# FM33LG0XX register map
File version: 1.0
CPU: SC123 r1p0, little endian, no MPU, no FPU, 3 interrupt priority bits
Registers are 32-bit, read-write, reset 0x0 unless marked. A register's access mark holds for its fields unless they carry their own. Offsets are from the block's base; [hi:lo] are bit positions; {n}, {i} and the like mark numbered series.

## SVD — SVD module information
Base 0x40012800
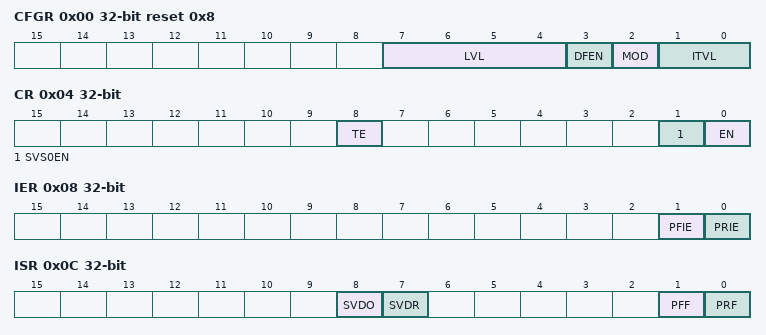
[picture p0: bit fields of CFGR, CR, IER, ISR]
0x00 CFGR reset 0x8 — SVD Config Register
  [7:4] LVL — LVL field description
  [3] DFEN — DFEN field description
  [2] MOD — MOD field description
  [1:0] ITVL — ITVL field description
0x04 CR access per field — SVD Control Register
  [8] TE rw — TE field description
  [1] SVS0EN wo — SVS0EN field description
  [0] EN rw — EN field description
0x08 IER — SVD Interrupt Enable Register
  [1] PFIE — PFIE field description
  [0] PRIE — PRIE field description
0x0C ISR access per field — SVD Interrupt Status Register
  [8] SVDO ro — SVDO field description
  [7] SVDR ro — SVDR field description
  [1] PFF rw — PFF field description
  [0] PRF rw — PRF field description
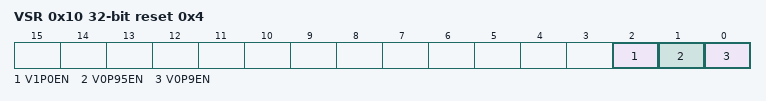
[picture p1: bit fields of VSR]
0x10 VSR reset 0x4 — SVD reference Voltage Select Register
  [2] V1P0EN — V1P0EN field description
  [1] V0P95EN — V0P95EN field description
  [0] V0P9EN — V0P9EN field description

## AES — AES module information
Base 0x40013800
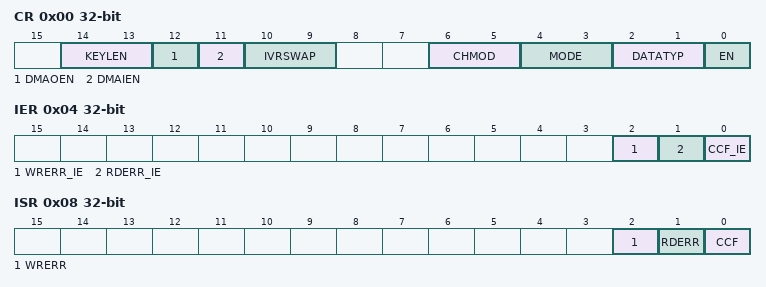
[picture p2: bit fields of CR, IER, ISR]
0x00 CR — AES Control Register
  [14:13] KEYLEN — KEYLEN field description
  [12] DMAOEN — DMAOEN field description
  [11] DMAIEN — DMAIEN field description
  [10:9] IVRSWAP — IVRSWAP field description
  [6:5] CHMOD — CHMOD field description
  [4:3] MODE — MODE field description
  [2:1] DATATYP — DATATYP field description
  [0] EN — EN field description
0x04 IER — AES Interrupt Enable Register
  [2] WRERR_IE — WRERR_IE field description
  [1] RDERR_IE — RDERR_IE field description
  [0] CCF_IE — CCF_IE field description
0x08 ISR — AES Interrupt Status Register
  [2] WRERR — WRERR field description
  [1] RDERR — RDERR field description
  [0] CCF — CCF field description
0x0C DIR — AES Data Input Register
  [31:0] DIN — DIN field description
0x10 DOR ro — AES Data Output Register
  [31:0] DOUT — DOUT field description
{0x14+4i} KEY{i} (i=0..7) — AES Key Register {i}
  [31:0] KEYx — KEYx field description
{0x34+4i} IVR{i} (i=0..3) — AES Initial Vector Register {i}
  [31:0] IVRx — IVRx field description
{0x44+4i} H{i} (i=0..3) — AES MultH parameter Register {i}
  [31:0] Hx — Hx field description

## RNG — RNG module information
Base 0x40013C00
0x00 CR — Random Number Generator Control Register
  [0] RNGEN — RNGEN field description
0x04 DOR ro — Random Number Generator Data Output Register
  [31:0] RNGOUT — RNGOUT field description
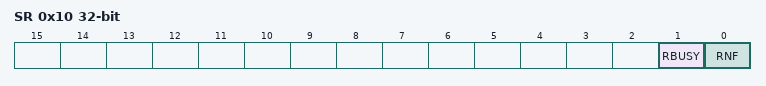
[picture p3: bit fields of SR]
0x10 SR access per field — Random Number Generator Status Register
  [1] RBUSY ro — RBUSY field description
  [0] RNF rw — RNF field description
0x14 CRC_CR — CRC Control Register
  [0] CRCEN — CRCEN field description
0x18 CRC_DIR — CRC Data input Register
  [31:0] CRCIN — CRCIN field description
0x1C CRC_SR — CRC Status Register
  [0] CRCDONE — CRCDONE field description

## OPA1 — OPA1 module information
Base 0x4001A000
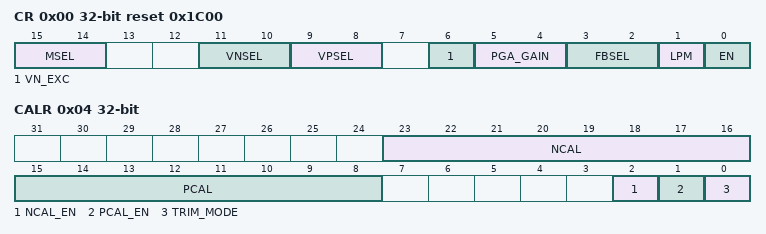
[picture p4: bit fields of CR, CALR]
0x00 CR reset 0x1C00 — OPA1 Control Register
  [15:14] MSEL — MSEL field description
  [11:10] VNSEL — VNSEL field description
  [9:8] VPSEL — VPSEL field description
  [6] VN_EXC — VN_EXC field description
  [5:4] PGA_GAIN — PGA_GAIN field description
  [3:2] FBSEL — FBSEL field description
  [1] LPM — LPM field description
  [0] EN — EN field description
0x04 CALR — OPA1 Calibration Register
  [23:16] NCAL — NCAL field description
  [15:8] PCAL — PCAL field description
  [2] NCAL_EN — NCAL_EN field description
  [1] PCAL_EN — PCAL_EN field description
  [0] TRIM_MODE — TRIM_MODE field description
0x08 COR ro — OPA1 Calibration Output Register
  [0] OUT — OUT field description

## COMP — COMP module information
Base 0x40015400
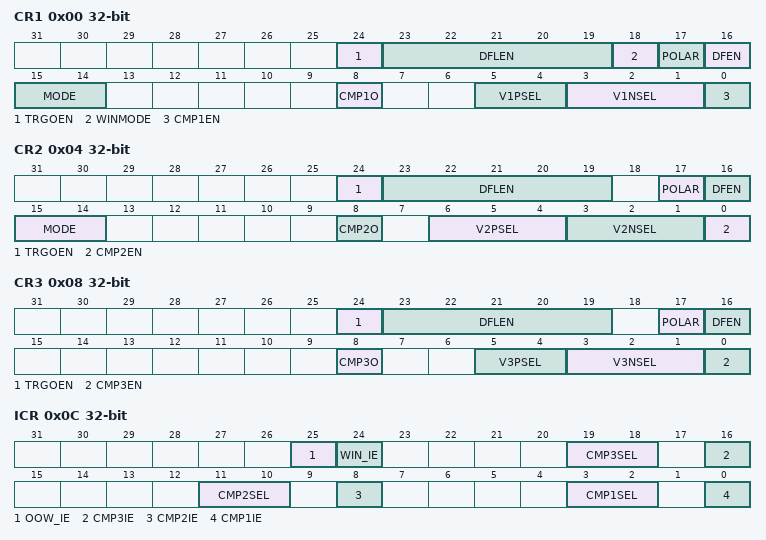
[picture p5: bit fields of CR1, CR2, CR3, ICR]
0x00 CR1 access per field — ComparatorControl Register 1
  [24] TRGOEN rw — TRGOEN field description
  [23:19] DFLEN rw — DFLEN field description
  [18] WINMODE rw — WINMODE field description
  [17] POLAR rw — POLAR field description
  [16] DFEN rw — DFEN field description
  [15:14] MODE rw — MODE field description
  [8] CMP1O ro — CMP1O field description
  [5:4] V1PSEL rw — V1PSEL field description
  [3:1] V1NSEL rw — V1NSEL field description
  [0] CMP1EN rw — CMP1EN field description
0x04 CR2 access per field — Comparator Control Register 2
  [24] TRGOEN rw — TRGOEN field description
  [23:19] DFLEN rw — DFLEN field description
  [17] POLAR rw — POLAR field description
  [16] DFEN rw — DFEN field description
  [15:14] MODE rw — MODE field description
  [8] CMP2O ro — CMP2O field description
  [6:4] V2PSEL rw — V2PSEL field description
  [3:1] V2NSEL rw — V2NSEL field description
  [0] CMP2EN rw — CMP2EN field description
0x08 CR3 access per field — Comparator Control Register 3
  [24] TRGOEN rw — TRGOEN field description
  [23:19] DFLEN rw — DFLEN field description
  [17] POLAR rw — POLAR field description
  [16] DFEN rw — DFEN field description
  [8] CMP3O ro — CMP3O field description
  [5:4] V3PSEL rw — V3PSEL field description
  [3:1] V3NSEL rw — V3NSEL field description
  [0] CMP3EN rw — CMP3EN field description
0x0C ICR — Comparator Interrupt Config Register
  [25] OOW_IE — OOW_IE field description
  [24] WIN_IE — WIN_IE field description
  [19:18] CMP3SEL — CMP3SEL field description
  [16] CMP3IE — CMP3IE field description
  [11:10] CMP2SEL — CMP2SEL field description
  [8] CMP2IE — CMP2IE field description
  [3:2] CMP1SEL — CMP1SEL field description
  [0] CMP1IE — CMP1IE field description
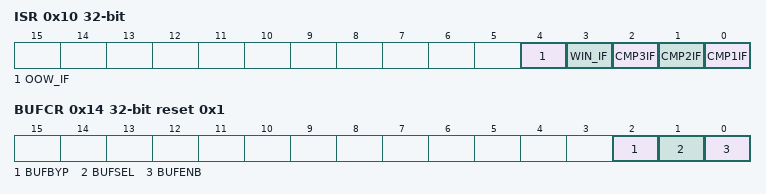
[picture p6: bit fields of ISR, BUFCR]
0x10 ISR — Comparator Interrupt Status Register
  [4] OOW_IF — OOW_IF field description
  [3] WIN_IF — WIN_IF field description
  [2] CMP3IF — CMP3IF field description
  [1] CMP2IF — CMP2IF field description
  [0] CMP1IF — CMP1IF field description
0x14 BUFCR reset 0x1 — Comparator Buffer Control Register
  [2] BUFBYP — BUFBYP field description
  [1] BUFSEL — BUFSEL field description
  [0] BUFENB — BUFENB field description
